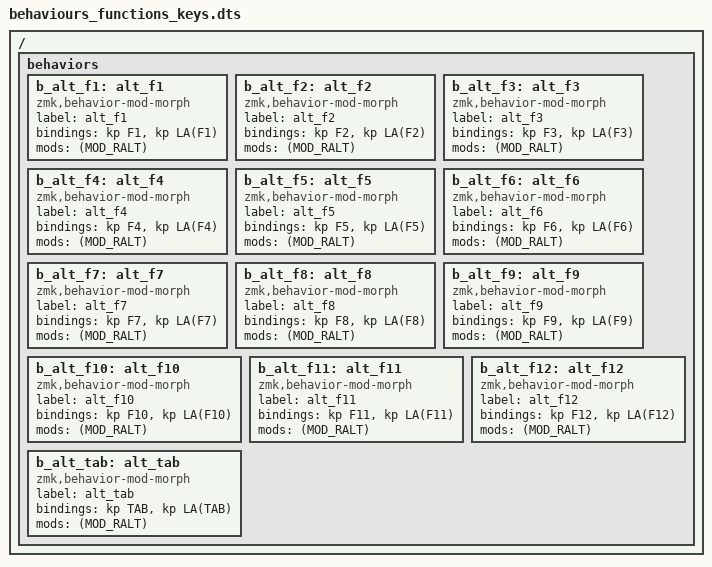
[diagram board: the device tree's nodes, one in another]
// Make sure settings.dtsi is included before this file

/ {

    behaviors {
        b_alt_f1: alt_f1 { compatible = "zmk,behavior-mod-morph"; label = "alt_f1"; #binding-cells = <0>; bindings = <&kp F1>, <&kp LA(F1)>; mods = <(MOD_RALT)>; };
        b_alt_f2: alt_f2 { compatible = "zmk,behavior-mod-morph"; label = "alt_f2"; #binding-cells = <0>; bindings = <&kp F2>, <&kp LA(F2)>; mods = <(MOD_RALT)>; };
        b_alt_f3: alt_f3 { compatible = "zmk,behavior-mod-morph"; label = "alt_f3"; #binding-cells = <0>; bindings = <&kp F3>, <&kp LA(F3)>; mods = <(MOD_RALT)>; };
        b_alt_f4: alt_f4 { compatible = "zmk,behavior-mod-morph"; label = "alt_f4"; #binding-cells = <0>; bindings = <&kp F4>, <&kp LA(F4)>; mods = <(MOD_RALT)>; };
        b_alt_f5: alt_f5 { compatible = "zmk,behavior-mod-morph"; label = "alt_f5"; #binding-cells = <0>; bindings = <&kp F5>, <&kp LA(F5)>; mods = <(MOD_RALT)>; };
        b_alt_f6: alt_f6 { compatible = "zmk,behavior-mod-morph"; label = "alt_f6"; #binding-cells = <0>; bindings = <&kp F6>, <&kp LA(F6)>; mods = <(MOD_RALT)>; };
        b_alt_f7: alt_f7 { compatible = "zmk,behavior-mod-morph"; label = "alt_f7"; #binding-cells = <0>; bindings = <&kp F7>, <&kp LA(F7)>; mods = <(MOD_RALT)>; };
        b_alt_f8: alt_f8 { compatible = "zmk,behavior-mod-morph"; label = "alt_f8"; #binding-cells = <0>; bindings = <&kp F8>, <&kp LA(F8)>; mods = <(MOD_RALT)>; };
        b_alt_f9: alt_f9 { compatible = "zmk,behavior-mod-morph"; label = "alt_f9"; #binding-cells = <0>; bindings = <&kp F9>, <&kp LA(F9)>; mods = <(MOD_RALT)>; };
        b_alt_f10: alt_f10 { compatible = "zmk,behavior-mod-morph"; label = "alt_f10"; #binding-cells = <0>; bindings = <&kp F10>, <&kp LA(F10)>; mods = <(MOD_RALT)>; };
        b_alt_f11: alt_f11 { compatible = "zmk,behavior-mod-morph"; label = "alt_f11"; #binding-cells = <0>; bindings = <&kp F11>, <&kp LA(F11)>; mods = <(MOD_RALT)>; };
        b_alt_f12: alt_f12 { compatible = "zmk,behavior-mod-morph"; label = "alt_f12"; #binding-cells = <0>; bindings = <&kp F12>, <&kp LA(F12)>; mods = <(MOD_RALT)>; };
        b_alt_tab: alt_tab { compatible = "zmk,behavior-mod-morph"; label = "alt_tab"; #binding-cells = <0>; bindings = <&kp TAB>, <&kp LA(TAB)>; mods = <(MOD_RALT)>; };
    };
};
